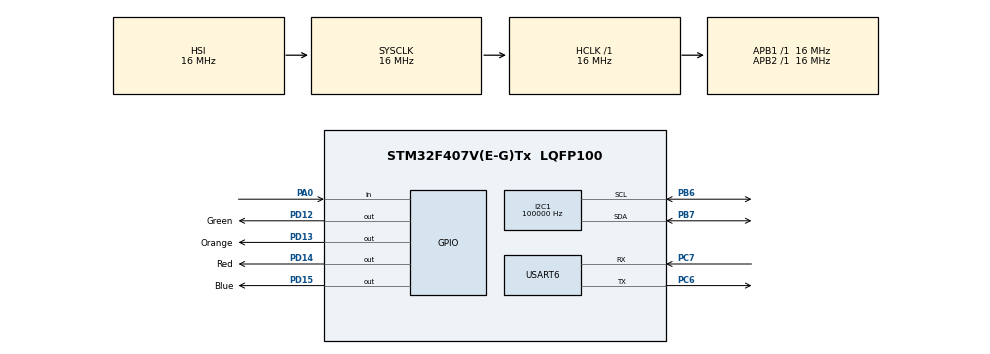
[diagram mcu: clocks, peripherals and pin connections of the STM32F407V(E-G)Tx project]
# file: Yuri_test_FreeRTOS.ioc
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FREERTOS.Tasks01=defaultTask,0,128,StartDefaultTask,Default,NULL
I2C1.ClockSpeed=100000
Mcu.Family=STM32F4
Mcu.Name=STM32F407V(E-G)Tx
Mcu.Package=LQFP100
NVIC.PriorityGroup=NVIC_PRIORITYGROUP_4
NVIC.USART6_IRQn=true\:5\:0\:false\:false\:true\:true
PA0-WKUP.Signal=GPIO_Input
PB6.GPIO_PuPdOD=GPIO_PULLUP
PB6.Mode=I2C
PB6.Signal=I2C1_SCL
PB7.GPIO_PuPdOD=GPIO_PULLUP
PB7.Mode=I2C
PB7.Signal=I2C1_SDA
PC6.Mode=Asynchronous
PC6.Signal=USART6_TX
PC7.Mode=Asynchronous
PC7.Signal=USART6_RX
PD12.GPIO_Label=Green
PD12.GPIO_PuPd=GPIO_PULLDOWN
PD12.Signal=GPIO_Output
PD13.GPIO_Label=Orange
PD13.GPIO_PuPd=GPIO_PULLDOWN
PD13.Signal=GPIO_Output
PD14.GPIO_Label=Red
PD14.GPIO_PuPd=GPIO_PULLDOWN
PD14.Signal=GPIO_Output
PD15.GPIO_Label=Blue
PD15.GPIO_PuPd=GPIO_PULLDOWN
PD15.Signal=GPIO_Output
ProjectManager.HeapSize=0x200
ProjectManager.StackSize=0x400
ProjectManager.TargetToolchain=SW4STM32
RCC.AHBFreq_Value=16000000
RCC.APB1Freq_Value=16000000
RCC.APB2Freq_Value=16000000
RCC.CortexFreq_Value=16000000
RCC.HSE_VALUE=25000000
RCC.HSI_VALUE=16000000
RCC.LSE_VALUE=32768
RCC.SYSCLKFreq_VALUE=16000000
RCC.VCOOutputFreq_Value=192000000
USART6.VirtualMode=VM_ASYNC
VP_FREERTOS_VS_ENABLE.Mode=Enabled
board=Yuri_test_FreeRTOS

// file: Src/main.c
/**
  ******************************************************************************
  * File Name          : main.c
  * Description        : Main program body
  ******************************************************************************
  * This notice applies to any and all portions of this file
  * that are not between comment pairs USER CODE BEGIN and
  * USER CODE END. Other portions of this file, whether
  * inserted by the user or by software development tools
  * are owned by their respective copyright owners.
  *
  * Copyright (c) 2017 STMicroelectronics International N.V.
  * All rights reserved.
  *
  * Redistribution and use in source and binary forms, with or without
  * modification, are permitted, provided that the following conditions are met:
  *
  * 1. Redistribution of source code must retain the above copyright notice,
  *    this list of conditions and the following disclaimer.
  * 2. Redistributions in binary form must reproduce the above copyright notice,
  *    this list of conditions and the following disclaimer in the documentation
  *    and/or other materials provided with the distribution.
  * 3. Neither the name of STMicroelectronics nor the names of other
  *    contributors to this software may be used to endorse or promote products
  *    derived from this software without specific written permission.
  * 4. This software, including modifications and/or derivative works of this
  *    software, must execute solely and exclusively on microcontroller or
  *    microprocessor devices manufactured by or for STMicroelectronics.
  * 5. Redistribution and use of this software other than as permitted under
  *    this license is void and will automatically terminate your rights under
  *    this license.
  *
  * THIS SOFTWARE IS PROVIDED BY STMICROELECTRONICS AND CONTRIBUTORS "AS IS"
  * AND ANY EXPRESS, IMPLIED OR STATUTORY WARRANTIES, INCLUDING, BUT NOT
  * LIMITED TO, THE IMPLIED WARRANTIES OF MERCHANTABILITY, FITNESS FOR A
  * PARTICULAR PURPOSE AND NON-INFRINGEMENT OF THIRD PARTY INTELLECTUAL PROPERTY
  * RIGHTS ARE DISCLAIMED TO THE FULLEST EXTENT PERMITTED BY LAW. IN NO EVENT
  * SHALL STMICROELECTRONICS OR CONTRIBUTORS BE LIABLE FOR ANY DIRECT, INDIRECT,
  * INCIDENTAL, SPECIAL, EXEMPLARY, OR CONSEQUENTIAL DAMAGES (INCLUDING, BUT NOT
  * LIMITED TO, PROCUREMENT OF SUBSTITUTE GOODS OR SERVICES; LOSS OF USE, DATA,
  * OR PROFITS; OR BUSINESS INTERRUPTION) HOWEVER CAUSED AND ON ANY THEORY OF
  * LIABILITY, WHETHER IN CONTRACT, STRICT LIABILITY, OR TORT (INCLUDING
  * NEGLIGENCE OR OTHERWISE) ARISING IN ANY WAY OUT OF THE USE OF THIS SOFTWARE,
  * EVEN IF ADVISED OF THE POSSIBILITY OF SUCH DAMAGE.
  *
  ******************************************************************************
  */
#include "main.h"
#include "stm32f4xx_hal.h"
#include "cmsis_os.h"

/* USER CODE BEGIN Includes */
#include "i2c_interface.h"
#include "led.h"
#include "uart_interface.h"
/* USER CODE END Includes */

I2C_HandleTypeDef hi2c1;

UART_HandleTypeDef huart6;

osThreadId defaultTaskHandle;

/* USER CODE BEGIN PV */
/* Private variables ---------------------------------------------------------*/

/* USER CODE END PV */

void SystemClock_Config(void);
static void MX_GPIO_Init(void);
static void MX_I2C1_Init(void);
static void MX_USART6_UART_Init(void);

/* USER CODE BEGIN PFP */
/* Private function prototypes -----------------------------------------------*/

/* USER CODE END PFP */

int main(void)
{

  /* MCU Configuration----------------------------------------------------------*/

  /* Reset of all peripherals, Initializes the Flash interface and the Systick. */
  HAL_Init();

  /* Configure the system clock */
  SystemClock_Config();

  /* Initialize all configured peripherals */
  MX_GPIO_Init();
  MX_I2C1_Init();
  MX_USART6_UART_Init();

  /* USER CODE BEGIN 2 */
	__HAL_UART_ENABLE_IT(&huart6,UART_IT_RXNE);
	__HAL_UART_ENABLE_IT(&huart6,UART_IT_TC);
  /* USER CODE END 2 */

  /* Create the thread(s) */
  /* definition and creation of defaultTask */

  /* USER CODE BEGIN RTOS_THREADS */

	//Here is all tasks that we need
  xTaskCreate( (void*)sampling_task,(const char*)"sampling_task",
		  STACK_SIZE, (void *)&hi2c1, tskIDLE_PRIORITY, NULL );

  xTaskCreate( (void*)led_task,(const char*)"led_task",
		  STACK_SIZE, NULL, tskIDLE_PRIORITY, NULL );

  xTaskCreate( (void*)uart_interface_task,(const char*)"uart_interface_task",
		  STACK_SIZE*2, NULL, tskIDLE_PRIORITY, NULL );

  /* USER CODE END RTOS_THREADS */

  /* Start scheduler */
  osKernelStart();

  /* We should never get here as control is now taken by the scheduler */

  /* Infinite loop */
  while (1)
  {

  }

}

/** System Clock Configuration
*/
void SystemClock_Config(void)
{

  RCC_OscInitTypeDef RCC_OscInitStruct;
  RCC_ClkInitTypeDef RCC_ClkInitStruct;

    /**Configure the main internal regulator output voltage
    */
  __HAL_RCC_PWR_CLK_ENABLE();

  __HAL_PWR_VOLTAGESCALING_CONFIG(PWR_REGULATOR_VOLTAGE_SCALE1);

    /**Initializes the CPU, AHB and APB busses clocks
    */
  RCC_OscInitStruct.OscillatorType = RCC_OSCILLATORTYPE_HSI;
  RCC_OscInitStruct.HSIState = RCC_HSI_ON;
  RCC_OscInitStruct.HSICalibrationValue = 16;
  RCC_OscInitStruct.PLL.PLLState = RCC_PLL_NONE;
  if (HAL_RCC_OscConfig(&RCC_OscInitStruct) != HAL_OK)
  {
    _Error_Handler(__FILE__, __LINE__);
  }

    /**Initializes the CPU, AHB and APB busses clocks
    */
  RCC_ClkInitStruct.ClockType = RCC_CLOCKTYPE_HCLK|RCC_CLOCKTYPE_SYSCLK
                              |RCC_CLOCKTYPE_PCLK1|RCC_CLOCKTYPE_PCLK2;
  RCC_ClkInitStruct.SYSCLKSource = RCC_SYSCLKSOURCE_HSI;
  RCC_ClkInitStruct.AHBCLKDivider = RCC_SYSCLK_DIV1;
  RCC_ClkInitStruct.APB1CLKDivider = RCC_HCLK_DIV1;
  RCC_ClkInitStruct.APB2CLKDivider = RCC_HCLK_DIV1;

  if (HAL_RCC_ClockConfig(&RCC_ClkInitStruct, FLASH_LATENCY_0) != HAL_OK)
  {
    _Error_Handler(__FILE__, __LINE__);
  }

    /**Configure the Systick interrupt time
    */
  HAL_SYSTICK_Config(HAL_RCC_GetHCLKFreq()/1000);

    /**Configure the Systick
    */
  HAL_SYSTICK_CLKSourceConfig(SYSTICK_CLKSOURCE_HCLK);

  /* SysTick_IRQn interrupt configuration */
  HAL_NVIC_SetPriority(SysTick_IRQn, 15, 0);
}

/* I2C1 init function */
static void MX_I2C1_Init(void)
{

  hi2c1.Instance = I2C1;
  hi2c1.Init.ClockSpeed = 100000;
  hi2c1.Init.DutyCycle = I2C_DUTYCYCLE_2;
  hi2c1.Init.OwnAddress1 = 0;
  hi2c1.Init.AddressingMode = I2C_ADDRESSINGMODE_7BIT;
  hi2c1.Init.DualAddressMode = I2C_DUALADDRESS_DISABLE;
  hi2c1.Init.OwnAddress2 = 0;
  hi2c1.Init.GeneralCallMode = I2C_GENERALCALL_DISABLE;
  hi2c1.Init.NoStretchMode = I2C_NOSTRETCH_DISABLE;
  if (HAL_I2C_Init(&hi2c1) != HAL_OK)
  {
    _Error_Handler(__FILE__, __LINE__);
  }

}

/* USART6 init function */
static void MX_USART6_UART_Init(void)
{

  huart6.Instance = USART6;
  huart6.Init.BaudRate = 115200;
  huart6.Init.WordLength = UART_WORDLENGTH_8B;
  huart6.Init.StopBits = UART_STOPBITS_1;
  huart6.Init.Parity = UART_PARITY_NONE;
  huart6.Init.Mode = UART_MODE_TX_RX;
  huart6.Init.HwFlowCtl = UART_HWCONTROL_NONE;
  huart6.Init.OverSampling = UART_OVERSAMPLING_16;
  if (HAL_UART_Init(&huart6) != HAL_OK)
  {
    _Error_Handler(__FILE__, __LINE__);
  }

}

/** Configure pins as
        * Analog
        * Input
        * Output
        * EVENT_OUT
        * EXTI
*/
static void MX_GPIO_Init(void)
{

  GPIO_InitTypeDef GPIO_InitStruct;

  /* GPIO Ports Clock Enable */
  __HAL_RCC_GPIOA_CLK_ENABLE();
  __HAL_RCC_GPIOD_CLK_ENABLE();
  __HAL_RCC_GPIOC_CLK_ENABLE();
  __HAL_RCC_GPIOB_CLK_ENABLE();

  /*Configure GPIO pin Output Level */
  HAL_GPIO_WritePin(GPIOD, Green_Pin|Orange_Pin|Red_Pin|Blue_Pin, GPIO_PIN_RESET);

  /*Configure GPIO pin : PA0 */
  GPIO_InitStruct.Pin = GPIO_PIN_0;
  GPIO_InitStruct.Mode = GPIO_MODE_INPUT;
  GPIO_InitStruct.Pull = GPIO_NOPULL;
  HAL_GPIO_Init(GPIOA, &GPIO_InitStruct);

  /*Configure GPIO pins : Green_Pin Orange_Pin Red_Pin Blue_Pin */
  GPIO_InitStruct.Pin = Green_Pin|Orange_Pin|Red_Pin|Blue_Pin;
  GPIO_InitStruct.Mode = GPIO_MODE_OUTPUT_PP;
  GPIO_InitStruct.Pull = GPIO_PULLDOWN;
  GPIO_InitStruct.Speed = GPIO_SPEED_FREQ_LOW;
  HAL_GPIO_Init(GPIOD, &GPIO_InitStruct);

}

/* USER CODE BEGIN 4 */

//void HAL_I2C_MasterTxCpltCallback(I2C_HandleTypeDef *hi2c){
//
// if(hi2c->Instance == I2C1){
//  I2C.Slave_Adress = 0x40;
//  I2C.Reg_Adress = 0x12;
//  I2C.Data = 0xFF;
//  HAL_I2C_Master_Transmit_IT(&hi2c1, I2C.Slave_Adress, (unsigned char*) &I2C.Reg_Adress, 2);
//  HAL_GPIO_WritePin(GPIOD, GPIO_PIN_12 | GPIO_PIN_13 | GPIO_PIN_14 |GPIO_PIN_15, GPIO_PIN_SET);
// }

/* USER CODE END 4 */

void _Error_Handler(char * file, int line)
{
  while(1)
  {
  }
}

/************************ (C) COPYRIGHT STMicroelectronics *****END OF FILE****/
